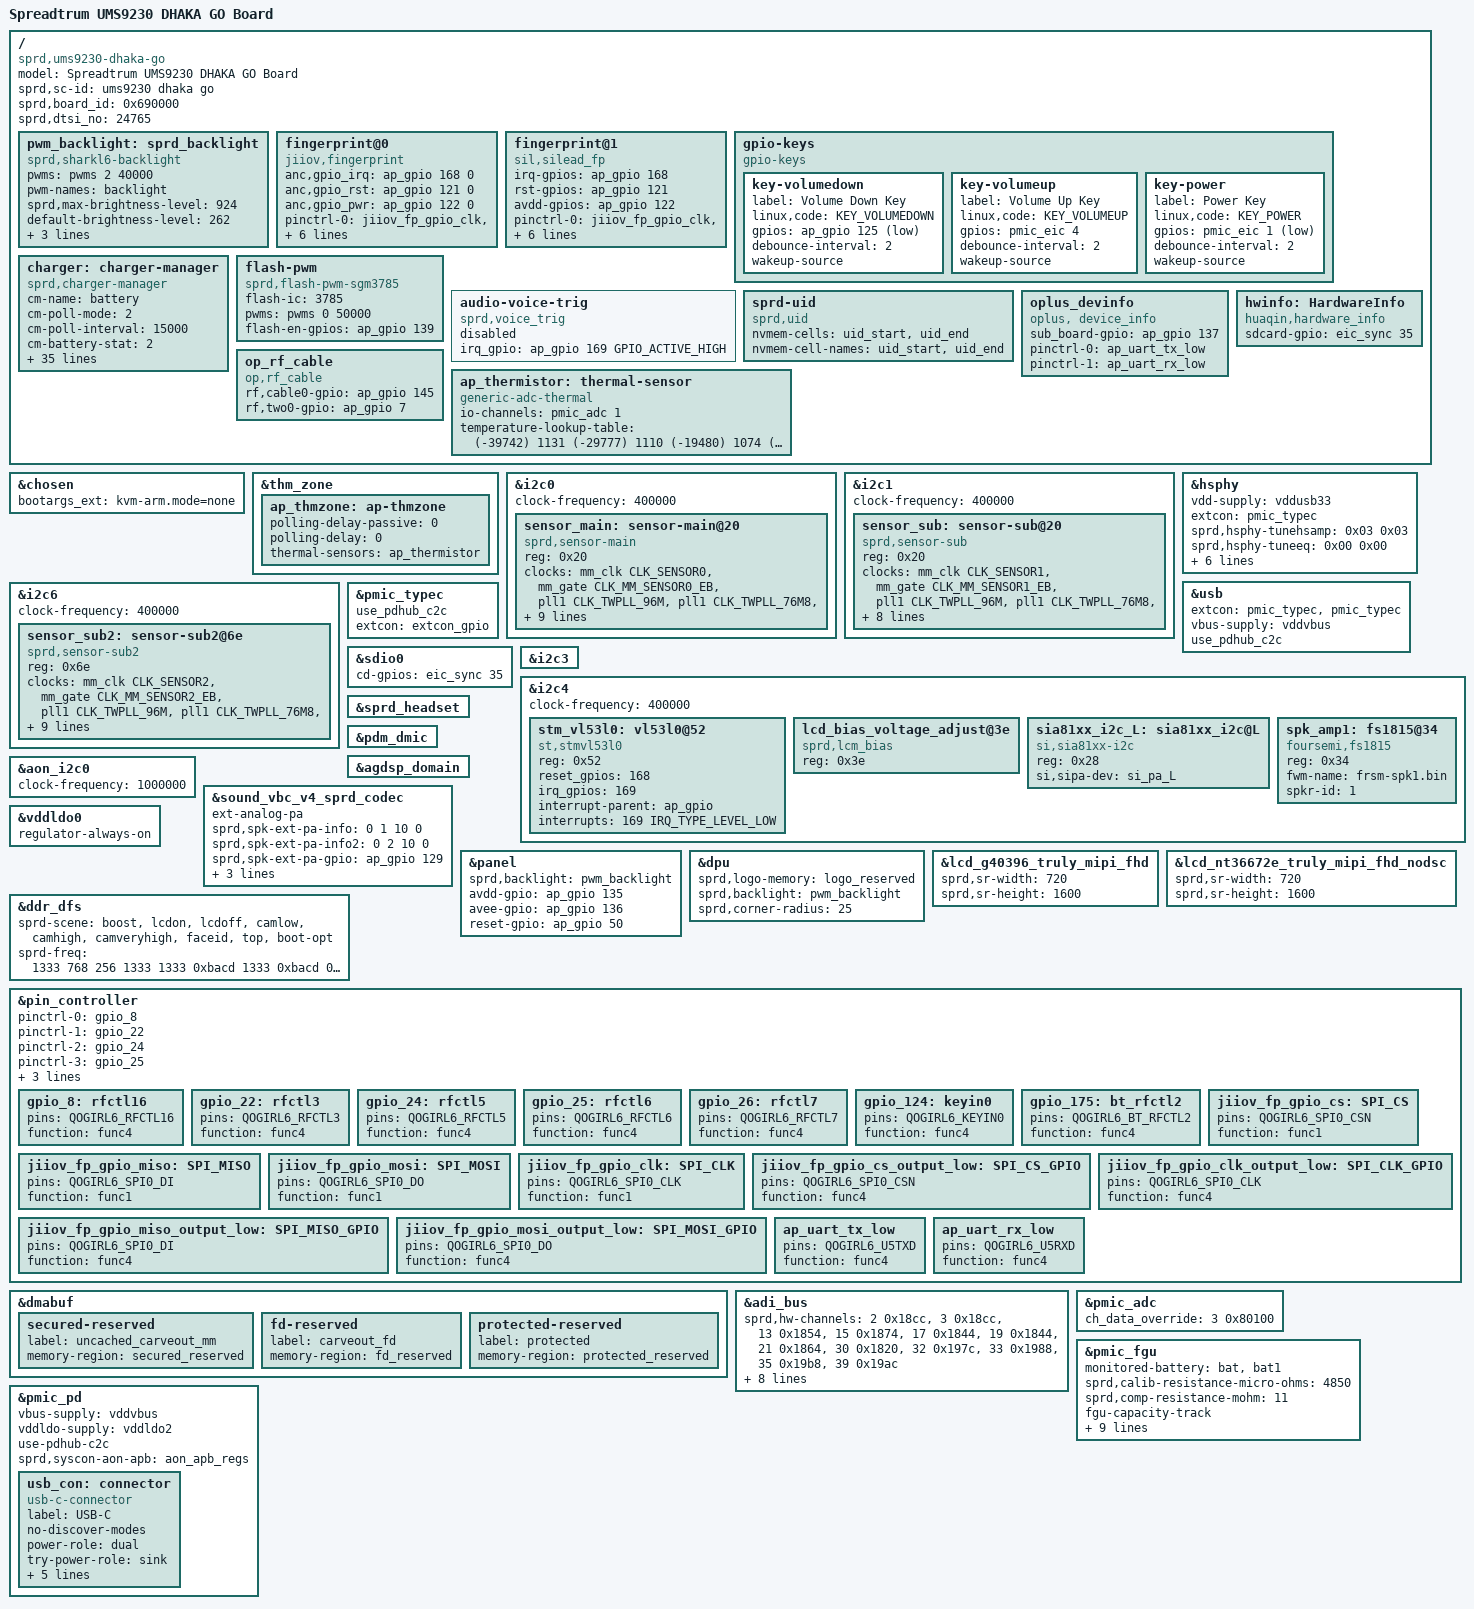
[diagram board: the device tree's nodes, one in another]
// SPDX-License-Identifier: GPL-2.0-only
/*
 * Spreadtrum Qogirl6 board common DTS file
 *
 * Copyright (C) 2021, Unisoc Inc.
 */

/dts-v1/;
/plugin/;
#include <dt-bindings/input/input.h>
#include <dt-bindings/gpio/gpio.h>
#include <dt-bindings/interrupt-controller/arm-gic.h>
#include <dt-bindings/clock/sprd,ums9230-clk.h>
#include <dt-bindings/mfd/sprd,sc2730-regs.h>
#include <dt-bindings/mfd/sprd,sc2730-mask.h>
#include <dt-bindings/usb/pd.h>
#include "lcd/lcd_gc9305_spi_qvga.dtsi"
#include "lcd/lcd_g40396_truly_mipi_fhd.dtsi"
#include "lcd/lcd_nt36672e_truly_mipi_fhd_nodsc.dtsi"
#include "lcd/lcd_icnl9916c_hjc_cd_mipi_hd.dtsi"
#include "lcd/lcd_icnl9916c_ld_hjc_mipi_hd.dtsi"
#include "lcd/lcd_icnl9916c_inx_mipi_hd.dtsi"
#include "lcd/lcd_hx83108a_lce_new_mipi_hd.dtsi"
#include "lcd/lcd_hx83108a_lce_mipi_hd.dtsi"
#include "lcd/lcd_hx83108a_boe_mipi_hd.dtsi"
#include "lcd/lcd_td4160_cw_mipi_hd.dtsi"
#include "lcd/lcd_td4160_cw_new_mipi_hd.dtsi"
#include "lcd/lcd_td4160_cw_old_mipi_hd.dtsi"
#include "lcd/lcd_ili9883c_txd_boe_new_mipi_hd.dtsi"
#include "lcd/lcd_ili79505a_txd_boe_mipi_hd.dtsi"
#include "lcd/lcd_td4160b_tm_mipi_hd.dtsi"
#include "lcd/lcd_ft8057p_ld_mipi_hd.dtsi"
#include "lcd/lcd_hx83108b_token_hkc_mipi_hd.dtsi"
#include "lcd/lcd_hx83108b_token_ctc_mipi_hd.dtsi"
#include "lcd/lcd_jd9365tg_hkc_hkc_mipi_hd.dtsi"
#include "lcd/lcd_jd9365tg_ld_inx_mipi_hd.dtsi"
//#include "lcd/lcd_nt36672e_truly_mipi_fhd.dtsi"
#include "lcd/lcd_jd9365tg_ld_ctc_mipi_hd.dtsi"
#include "lcd/lcd_dummy_mipi.dtsi"
#include "touchscreen/ums9230-spi3-gpio144-145-dhaka-tp.dtsi"
#include "reserved-memory/ums9230-dhaka-go-overlay.dtsi"
#include "ums9230/wcn.dtsi"
#include "wcn/wcn_modules.h"
#include "wcn/chip/wcn-integrate-sharkl6-register.dtsi"
#include "battery/latteT_OPLUS_ATL_4V48_6000mah.dtsi"
#include "battery/latteT_OPLUS_ATL_4V48_6300mah.dtsi"
#include "Spard-sia81x9.dtsi"
#include "sprd-fs1815.dtsi"
/ {

	model = "Spreadtrum UMS9230 DHAKA GO Board";

	compatible = "sprd,ums9230-dhaka-go";

	sprd,sc-id = "ums9230 dhaka go";

	sprd,board_id = <0x690000>; //XXYY00:base board,XXYY00~XXYYFF:customize board

	sprd,dtsi_no = "24765";

	fragment {
		target-path = "/";
		__overlay__ {
			pwm_backlight: sprd_backlight {
				compatible = "sprd,sharkl6-backlight";
				pwms = <&pwms 2 40000>;
				pwm-names = "backlight";
				sprd,max-brightness-level = <924>;
				default-brightness-level = <262>;
				sprd,brightness-scale = <1023>;
				brightness-levels = <
							  0   3   4   5   6   7
					  8   9  10  11  12  13  14  16  17  18
					 19  20  21  22  23  24  25  26  27  28
					 29  31  33  35  37  39  41  43  45  47
					 48  50  52  54  56  58  60  62  64  67
					 69  72  74  76  78  80  82  84  86  88
					 90  92  94  96  98 100 102 104 107 109
					112 114 116 118 120 122 124 126 128 130
					132 134 136 138 140 142 144 147 149 151
					154 156 158 160 162 164 166 168 170 172
					175 178 181 184 187 190 193 196 199 203
					205 208 211 214 217 220 223 226 229 234
					237 240 243 247 250 253 256 259 263 266
					269 270 274 277 280 283 287 290 294 297
					300 303 307 310 314 318 325 329 334 339
					340 343 347 350 354 358 365 369 374 380
					382 385 389 392 396 400 407 411 416 422
					426 430 434 438 442 446 452 457 460 464
					470 474 480 486 492 498 504 508 512 516
					522 527 532 536 540 545 550 555 561 568
					574 579 584 589 594 600 605 610 615 620
					625 630 635 641 647 652 657 662 667 673
					688 694 700 706 712 716 720 725 730 735
					740 746 752 758 764 770 776 782 790 798
					803 810 817 825 832 840 845 850 855 861
					866 872 878 884 890 896 903 911 918 924
				>;
			};

			fingerprint@0 {
				compatible = "jiiov,fingerprint";
				anc,gpio_irq = <&ap_gpio 168 0>;
				anc,gpio_rst = <&ap_gpio 121 0>;
				anc,gpio_pwr = <&ap_gpio 122 0 >;
				pinctrl-names = "anc_spi_active", "anc_spi_output_low";
				pinctrl-0 = <&jiiov_fp_gpio_clk>, <&jiiov_fp_gpio_mosi>, <&jiiov_fp_gpio_miso>, <&jiiov_fp_gpio_cs>;
				pinctrl-1 = <&jiiov_fp_gpio_clk_output_low>, <&jiiov_fp_gpio_mosi_output_low>, <&jiiov_fp_gpio_cs_output_low>,<&jiiov_fp_gpio_miso_output_low>;
			};

			fingerprint@1 {
				compatible = "sil,silead_fp";
				irq-gpios = <&ap_gpio 168 0>;
				rst-gpios = <&ap_gpio 121 0>;
				avdd-gpios = <&ap_gpio 122 0 >;
				pinctrl-names = "anc_spi_active", "anc_spi_output_low";
				pinctrl-0 = <&jiiov_fp_gpio_clk>, <&jiiov_fp_gpio_mosi>, <&jiiov_fp_gpio_miso>, <&jiiov_fp_gpio_cs>;
				pinctrl-1 = <&jiiov_fp_gpio_clk_output_low>, <&jiiov_fp_gpio_mosi_output_low>, <&jiiov_fp_gpio_cs_output_low>,<&jiiov_fp_gpio_miso_output_low>;
			};

			gpio-keys {
				compatible = "gpio-keys";

				key-volumedown {
					label = "Volume Down Key";
					linux,code = <KEY_VOLUMEDOWN>;
					gpios = <&ap_gpio 125 GPIO_ACTIVE_LOW>;
					debounce-interval = <2>;
					wakeup-source;
				};

				key-volumeup {
					label = "Volume Up Key";
					linux,code = <KEY_VOLUMEUP>;
					gpios = <&pmic_eic 4 GPIO_ACTIVE_HIGH>;
					debounce-interval = <2>;
					wakeup-source;
				};

				key-power {
					label = "Power Key";
					linux,code = <KEY_POWER>;
					gpios = <&pmic_eic 1 GPIO_ACTIVE_LOW>;
					debounce-interval = <2>;
					wakeup-source;
				};
			};

			charger: charger-manager {
				status = "okay";
				compatible = "sprd,charger-manager";
				cm-name = "battery";
				cm-poll-mode = <2>;
				cm-poll-interval = <15000>;
				cm-battery-stat = <2>;

				cm-fullbatt-vchkdrop-ms = <30000>;
				cm-fullbatt-vchkdrop-volt = <60000>;
				cm-fullbatt-capacity = <100>;
				/*Charge pump target charge current*/
				cm-cp-taper-current = <1000000>;

				cm-chargers = "sgm41512_charger";
				//cm-charge-pumps = "bq2597x-standalone";
				//cm-wireless-chargers = "nu1619_wireless_charger";
				//cm-wireless-charge-pump-converters = "hl1506_cp_converter";
				cm-fuel-gauge = "sc27xx-fgu";

				/* in deci centigrade */
				cm-battery-cold = <200>;
				cm-battery-cold-in-minus;
				cm-battery-hot = <800>;
				cm-battery-temp-diff = <100>;

				/* Allow charging for 6hr */
				cm-charging-max = <21600000>;
				/* recovery charging after stop charging 45min */
				cm-discharging-max = <2700000>;

				/* the interval to feed charger watchdog */
				cm-wdt-interval = <60>;

				/* drop voltage in microVolts to allow shutdown */
				cm-shutdown-voltage = <3100000>;

				/* when 99% of the time is exceeded, it will be forced to 100% */
				cm-tickle-time-out = <1500>;

				/* how much time to allow capacity change */
				cm-one-cap-time = <30>;
				cm-thermal-zone = "board-thmzone";
				/* when the safe charging voltage is exceeded, stop charging */
				cm-charge-voltage-max = <6500000>;
				cm-fast-charge-voltage-max = <10500000>;
				cm-flash-charge-voltage-max = <12000000>;
				cm-wireless-charge-voltage-max = <6500000>;
				cm-wireless-fast-charge-voltage-max = <12000000>;
				/* drop voltage in microVolts to restart charging */
				cm-charge-voltage-drop = <700000>;
				cm-fast-charge-voltage-drop = <700000>;
				cm-flash-charge-voltage-drop = <1000000>;
				cm-wireless-charge-voltage-drop = <700000>;
				cm-wireless-fast-charge-voltage-drop = <1000000>;

				/* sprd_fchg parameter */
				sprd,support-fchg;
				// sprd,support-pd-pps;
				//sprd,pd-fixed-max-microwatt = <18000000>;

				cm-cap-remap-table = <1 2 3>, <2 3 2>, <98 99 2>, <99 100 3>;

				//monitored-battery = <&bat>;
				cm-keep-awake;

				//phys = <&hsphy>;
				//extcon = <&pmic_typec>, <&pmic_pd>;
				//pd-extcon-enable;
				phys = <&hsphy>;
				pd-extcon-enable;
				extcon = <&pmic_typec>, <&pmic_pd>;
				use-typec-extcon;

			};

			flash-pwm {
					compatible = "sprd,flash-pwm-sgm3785";
					flash-ic = <3785>;
					pwms = <&pwms 0 50000>;
					flash-en-gpios = <&ap_gpio 139 0>;
					status = "okay";
				};

			audio-voice-trig {
				status = "disable";
				compatible = "sprd,voice_trig";
				irq_gpio = <&ap_gpio 169 GPIO_ACTIVE_HIGH>;
			};

			sprd-uid {
				compatible = "sprd,uid";
				nvmem-cells = <&uid_start>, <&uid_end>;
				nvmem-cell-names = "uid_start", "uid_end";
			};

			oplus_devinfo:oplus_devinfo {
				compatible = "oplus, device_info";
				sub_board-gpio = <&ap_gpio 137 0>;

				/*pinctrl, change ap_uart0 to  inf1*/
				pinctrl-names = "ap_uart_tx_low", "ap_uart_rx_low";

				pinctrl-0 = <&ap_uart_tx_low>;
				pinctrl-1 = <&ap_uart_rx_low>;

				status = "okay";
			};

			hwinfo:HardwareInfo {
				compatible = "huaqin,hardware_info";
				sdcard-gpio = <&eic_sync 35 0>;
				status = "okay";
			};

			/*Used to check the RF antenna*/
			op_rf_cable {
				compatible = "op,rf_cable";
				status = "okay";
				rf,cable0-gpio = <&ap_gpio 145 0>;
				rf,two0-gpio = <&ap_gpio 7 0>;
			};

			ap_thermistor:thermal-sensor {
				compatible = "generic-adc-thermal";
				#thermal-sensor-cells = <0>;
				io-channels = <&pmic_adc 1>;
				io-channel-names = "sensor-channel";
				temperature-lookup-table = <
						(-39742) 1131
						(-29777) 1110
						(-19480) 1074
						(-4679) 983
						10110 838
						24805 654
						44922 413
						54903 316
						64895 238
						74884 178
						84883 133
						94883 100
						104880 75
						114889 57
						124872 43 >;
			};
		};
	};
};

&chosen {
	bootargs_ext = "kvm-arm.mode=none";
};

&thm_zone {
	ap_thmzone: ap-thmzone {
		polling-delay-passive = <0>;
		polling-delay = <0>;
		thermal-sensors = <&ap_thermistor>;
	};
};

&i2c0 {
	status = "okay";
	clock-frequency = <400000>;
	#address-cells = <1>;
	#size-cells = <0>;

	sensor_main: sensor-main@20 {
		compatible = "sprd,sensor-main";
		reg = <0x20>;
		clock-names = "clk_src","sensor_eb",
			"clk_96m","clk_76m8",
			"clk_48m","clk_26m";
		clocks = <&mm_clk CLK_SENSOR0>,<&mm_gate CLK_MM_SENSOR0_EB>,
				<&pll1 CLK_TWPLL_96M>,<&pll1 CLK_TWPLL_76M8>,
				<&pll1 CLK_TWPLL_48M>,<&ext_26m>;
		vddio-supply = <&vddcamio>;
		vddcama-supply = <&vddcama0>;
		vddcamd-supply = <&vddcamd0>;
		vddcammot-supply = <&vddcammot>;
		reset-gpios = <&ap_gpio 44 0>;
		sprd,phyid = <2>;
		csi = <&csi0>;
		power-domains = <&mm_domain>;
	};
};

&i2c1 {
	status = "okay";
	clock-frequency = <400000>;
	#address-cells = <1>;
	#size-cells = <0>;

	sensor_sub: sensor-sub@20 {
		compatible = "sprd,sensor-sub";
		reg = <0x20>;
		clock-names = "clk_src","sensor_eb",
			"clk_96m","clk_76m8",
			"clk_48m","clk_26m";
		clocks = <&mm_clk CLK_SENSOR1>,<&mm_gate CLK_MM_SENSOR1_EB>,
				<&pll1 CLK_TWPLL_96M>,<&pll1 CLK_TWPLL_76M8>,
				<&pll1 CLK_TWPLL_48M>,<&ext_26m>;
		vddio-supply = <&vddcamio>;
		vddcama-supply = <&vddcama1>;
		vddcamd-supply = <&vddcamd1>;
		reset-gpios = <&ap_gpio 41 0>;
		sprd,phyid = <0>;
		csi = <&csi1>;
		power-domains = <&mm_domain>;
	};


};

&i2c6 {
	status = "okay";
	clock-frequency = <400000>;
	#address-cells = <1>;
	#size-cells = <0>;

	sensor_sub2: sensor-sub2@6e {
		compatible = "sprd,sensor-sub2";
		reg = <0x6e>;
		clock-names = "clk_src","sensor_eb",
			"clk_96m","clk_76m8",
			"clk_48m","clk_26m";
		clocks = <&mm_clk CLK_SENSOR2>,<&mm_gate CLK_MM_SENSOR2_EB>,
			<&pll1 CLK_TWPLL_96M>,<&pll1 CLK_TWPLL_76M8>,
			<&pll1 CLK_TWPLL_48M>,<&ext_26m>;
		vddio-supply = <&vddcamio>;
		avdd-gpios = <&ap_gpio 130 0>;
		vddcamd-supply = <&vddcamd1>;
		vddcammot-supply = <&vddcammot>;
		mot-gpios = <&ap_gpio 112 0>;
		reset-gpios = <&ap_gpio 114 0>;
	/*	power-down-gpios = <&ap_gpio 40 0>;*/
		sprd,phyid = <3>;
		csi = <&csi2>;
	};
};

&hsphy {
	vdd-supply = <&vddusb33>;
	extcon = <&pmic_typec>;
	/* first value is device eye-patt setting, the second is host */
	sprd,hsphy-tunehsamp = /bits/ 8 <0x03 0x03>;
	sprd,hsphy-tuneeq = /bits/ 8 <0x00 0x00>;
	sprd,hsphy-tfregres = /bits/ 8 <0x0a 0x0a>;
	sprd,hsphy-tfhsres = /bits/ 8 <0x16 0x16>;
	sprd,hsphy-tunerise = /bits/ 8 <0x01 0x01>;
	sprd,hsphy-tuneotg = /bits/ 8 <0x07 0x07>;
	sprd,hsphy-tunedsc = /bits/ 8 <0x03 0x03>;
	sprd,hsphy-tunesq = /bits/ 8 <0x08 0x08>;
	status = "okay";
};

&usb {
	extcon = <&pmic_typec>, <&pmic_typec>;
	vbus-supply = <&vddvbus>;
	status = "okay";
	use_pdhub_c2c;
};

&pmic_typec {
	use_pdhub_c2c;
	extcon = <&extcon_gpio>;
	status = "okay";
};

&sdio0 {
	cd-gpios = <&eic_sync 35 GPIO_ACTIVE_HIGH>;
};

&i2c3 {
	status = "okay";
	#address-cells = <1>;
	#size-cells = <0>;
};

&i2c4 {
	status = "okay";
	#address-cells = <1>;
	#size-cells = <0>;
	clock-frequency = <400000>;

	stm_vl53l0: vl53l0@52 {
		compatible = "st,stmvl53l0";
		reg = <0x52>;
		reset_gpios = <168>;
		irq_gpios = <169>;
		interrupt-parent = <&ap_gpio>;
		interrupts = <169 IRQ_TYPE_LEVEL_LOW>;
	};

	/* panzhibin@MULTIMEDIA.DISPLAY.LCD, 2023/04/13, add for lcm bias set */
	lcd_bias_voltage_adjust@3e {
		compatible = "sprd,lcm_bias";
		reg = <0x3e>;
	};

        sia81xx_i2c_L: sia81xx_i2c@L {
		compatible = "si,sia81xx-i2c";
		reg = <0x28>;
		si,sipa-dev = <&si_pa_L>;
	};

        spk_amp1:fs1815@34 {
		compatible = "foursemi,fs1815";
		reg = <0x34>;
		fwm-name = "frsm-spk1.bin";
		spkr-id = <1>;
		status = "ok";
	};
};

&aon_i2c0 {
	status = "okay";
	clock-frequency = <1000000>;
};

&sprd_headset {
	status = "okay";
};

&pdm_dmic {
	status = "okay";
};

&agdsp_domain {
	status = "okay";
};

&sound_vbc_v4_sprd_codec {
        status = "okay";
        /*ext_control_type, hook selection, mode, gpio share*/
        ext-analog-pa;
        sprd,spk-ext-pa-info = <0 1 10 0>;
        sprd,spk-ext-pa-info2 = <0 2 10 0>;
        sprd,spk-ext-pa-gpio = <&ap_gpio 129 0>;
        si,sia81xx-max-num = <1>;
        si,sia81xx-aux-devs = <&si_pa_L>;
        si,sia81xx-aux-devs-prefix = "SpkrLeft";
};

&vddldo0 {
	regulator-always-on;
};

&panel {
	sprd,backlight = <&pwm_backlight>;
	avdd-gpio = <&ap_gpio 135 GPIO_ACTIVE_HIGH>;
	avee-gpio = <&ap_gpio 136 GPIO_ACTIVE_HIGH>;
	reset-gpio = <&ap_gpio 50 GPIO_ACTIVE_HIGH>;
};

&dpu {
	sprd,logo-memory = <&logo_reserved>;

	sprd,backlight = <&pwm_backlight>;

	sprd,corner-radius = <25>;
};

&lcd_g40396_truly_mipi_fhd {
	sprd,sr-width = <720>;
	sprd,sr-height = <1600>;
};

&lcd_nt36672e_truly_mipi_fhd_nodsc {
	sprd,sr-width = <720>;
	sprd,sr-height = <1600>;
};

&ddr_dfs {
	  sprd-scene = "boost", "lcdon", "lcdoff", "camlow",
			"camhigh", "camveryhigh", "faceid", "top", "boot-opt";
	  sprd-freq = <1333 768 256 1333 1333 0xbacd 1333 0xbacd 0xbacd>;
};

&pin_controller {
	pinctrl-names =
	/* rfctl16 ,rfctl3, rfctl5 */
	"gpio_8", "gpio_22", "gpio_24",
	/* rfctl6, rfctl7, keyin0 */
	"gpio_25", "gpio_26", "gpio_124",
	/* bt_rfctl2 */
	"gpio_175";
	pinctrl-0 = <&gpio_8>;
	pinctrl-1 = <&gpio_22>;
	pinctrl-2 = <&gpio_24>;
	pinctrl-3 = <&gpio_25>;
	pinctrl-4 = <&gpio_26>;
	pinctrl-5 = <&gpio_124>;
	pinctrl-6 = <&gpio_175>;

	gpio_8: rfctl16 {
		pins = "QOGIRL6_RFCTL16";
		function = "func4";
	};

	gpio_22: rfctl3 {
		pins = "QOGIRL6_RFCTL3";
		function = "func4";
	};

	gpio_24: rfctl5 {
		pins = "QOGIRL6_RFCTL5";
		function = "func4";
	};

	gpio_25: rfctl6 {
		pins = "QOGIRL6_RFCTL6";
		function = "func4";
	};

	gpio_26: rfctl7 {
		pins = "QOGIRL6_RFCTL7";
		function = "func4";
	};

	gpio_124: keyin0 {
		pins = "QOGIRL6_KEYIN0";
		function = "func4";
	};

	gpio_175: bt_rfctl2 {
		pins = "QOGIRL6_BT_RFCTL2";
		function = "func4";
	};

	jiiov_fp_gpio_cs:SPI_CS {
 		 pins = "QOGIRL6_SPI0_CSN";
 		 function = "func1";

 	};

 	jiiov_fp_gpio_miso:SPI_MISO {
 		 pins = "QOGIRL6_SPI0_DI";
 		 function = "func1";
 	};

 	jiiov_fp_gpio_mosi:SPI_MOSI {
 		 pins = "QOGIRL6_SPI0_DO";
 		 function = "func1";
 	};

 	jiiov_fp_gpio_clk:SPI_CLK {
 		 pins = "QOGIRL6_SPI0_CLK";
 		 function = "func1";
 	};

 	jiiov_fp_gpio_cs_output_low:SPI_CS_GPIO {
 		 pins = "QOGIRL6_SPI0_CSN";
 		 function = "func4";
 	};

 	jiiov_fp_gpio_miso_output_low:SPI_MISO_GPIO {
 		 pins = "QOGIRL6_SPI0_DI";
 		 function = "func4";
 	};

 	jiiov_fp_gpio_mosi_output_low:SPI_MOSI_GPIO {
 		 pins = "QOGIRL6_SPI0_DO";
 		 function = "func4";
 	};

 	jiiov_fp_gpio_clk_output_low:SPI_CLK_GPIO {
 		 pins = "QOGIRL6_SPI0_CLK";
 		 function = "func4";
 	};

 	ap_uart_tx_low: ap_uart_tx_low {
 	 	pins = "QOGIRL6_U5TXD";
 	 	function = "func4";
 	};

 	ap_uart_rx_low: ap_uart_rx_low {
 	 	pins = "QOGIRL6_U5RXD";
 	 	function = "func4";
 	};
};

&dmabuf {

	secured-reserved {
		label = "uncached_carveout_mm";
		memory-region = <&secured_reserved>;
	};

	fd-reserved {
		label = "carveout_fd";
		memory-region = <&fd_reserved>;
	};

	protected-reserved {
		label = "protected";
		memory-region = <&protected_reserved>;
	};
};

&adi_bus {
	sprd,hw-channels = <2 0x18cc>, <3 0x18cc>, <13 0x1854>, <15 0x1874>,
			<17 0x1844>, <19 0x1844>, <21 0x1864>, <30 0x1820>,
			<32 0x197c>, <33 0x1988>, <35 0x19b8>, <39 0x19ac>;
	sprd,hw-channels0 = <2 0x18cc>, <3 0x18cc>, <13 0x1874>, <15 0x1874>,
			<17 0x1844>, <19 0x1854>, <21 0x1864>, <30 0x1820>,
			<32 0x197c>, <33 0x1988>, <35 0x19b8>, <39 0x19ac>;
	sprd,hw-channels1 = <2 0x18cc>, <3 0x18cc>, <13 0x1854>, <15 0x1874>,
			<17 0x1844>, <19 0x1844>, <21 0x1864>, <30 0x1820>,
			<32 0x197c>, <33 0x1988>, <35 0x19b8>, <39 0x19ac>;
};

&pmic_adc {
	ch_data_override = <3 0x80100>;
};

&pmic_fgu {
	monitored-battery = <&bat>, <&bat1>;
//	fgu-cap-remap-table = <1 2 3>, <2 3 2>, <98 99 2>, <99 100 3>;
	sprd,calib-resistance-micro-ohms = <4850>;
	sprd,comp-resistance-mohm = <11>;

	fgu-capacity-track;
	phys = <&hsphy>;
	io-channels = <&pmic_adc 0>, <&pmic_adc 3>, <&pmic_adc 14>;
	io-channel-names = "bat-temp", "batt_id", "charge-vol";

	sprd,relax-counter-threshold = <580>;
	sprd,relax-current-threshold = <30>;
	sprd,capacity-sleep-calibration;

	sprd,capacity-boot-calibration;
	use-typec-extcon;
	extcon = <&pmic_typec>;
};

&pmic_pd {
	status = "okay";
	vbus-supply = <&vddvbus>;
	vddldo-supply = <&vddldo2>;
	use-pdhub-c2c;
	sprd,syscon-aon-apb = <&aon_apb_regs>;
	usb_con: connector {
		compatible = "usb-c-connector";
		label = "USB-C";
		no-discover-modes;
		power-role = "dual";
		try-power-role = "sink";
		source-pdos = <PDO_FIXED(5000, 400, PDO_FIXED_USB_COMM |
				PDO_FIXED_DUAL_ROLE | PDO_FIXED_DATA_SWAP)>;
		sink-pdos = <PDO_FIXED(5000, 3000, PDO_FIXED_USB_COMM)
				PDO_PPS_APDO(3300, 11000, 4800)>;
		op-sink-microwatt = <10000000>;
	};
};
#include "ums9230-latteT-charger.dtsi"
